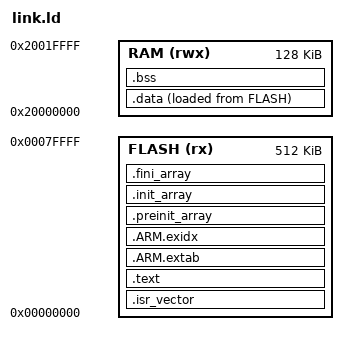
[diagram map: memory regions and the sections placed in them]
/* Cortex-M4 테스트 픽스처 공용 링커 스크립트.
   Flash 0x00000000(STM Simulator: 0x08000000 별칭, QEMU mps2-an386: SSRAM1), RAM 0x20000000 128 KB. */
ENTRY(Reset_Handler)
MEMORY
{
  FLASH (rx)  : ORIGIN = 0x00000000, LENGTH = 512K
  RAM   (rwx) : ORIGIN = 0x20000000, LENGTH = 128K
}
_estack = ORIGIN(RAM) + LENGTH(RAM);
_min_stack = 0x2000;
SECTIONS
{
  .isr_vector : { . = ALIGN(4); KEEP(*(.isr_vector)) . = ALIGN(4); } > FLASH
  .text :
  {
    . = ALIGN(4);
    *(.text) *(.text*) *(.glue_7) *(.glue_7t) *(.eh_frame)
    KEEP(*(.init)) KEEP(*(.fini))
    *(.rodata) *(.rodata*)
    . = ALIGN(4);
  } > FLASH
  .ARM.extab : { *(.ARM.extab* .gnu.linkonce.armextab.*) } > FLASH
  .ARM.exidx : { __exidx_start = .; *(.ARM.exidx*) __exidx_end = .; } > FLASH
  .preinit_array : { PROVIDE_HIDDEN(__preinit_array_start = .); KEEP(*(.preinit_array*)) PROVIDE_HIDDEN(__preinit_array_end = .); } > FLASH
  .init_array : { PROVIDE_HIDDEN(__init_array_start = .); KEEP(*(SORT(.init_array.*))) KEEP(*(.init_array*)) PROVIDE_HIDDEN(__init_array_end = .); } > FLASH
  .fini_array : { PROVIDE_HIDDEN(__fini_array_start = .); KEEP(*(SORT(.fini_array.*))) KEEP(*(.fini_array*)) PROVIDE_HIDDEN(__fini_array_end = .); } > FLASH
  _sidata = LOADADDR(.data);
  .data : { . = ALIGN(4); _sdata = .; *(.data) *(.data*) . = ALIGN(4); _edata = .; } > RAM AT> FLASH
  .bss (NOLOAD) : { . = ALIGN(4); _sbss = .; __bss_start__ = _sbss; *(.bss) *(.bss*) *(COMMON) . = ALIGN(4); _ebss = .; __bss_end__ = _ebss; } > RAM
  . = ALIGN(8);
  PROVIDE(end = .);
  PROVIDE(_end = .);

}
